# COMPUTE_CLUSTER_ARM_COREPACK_0_COMPUTE_CLUSTER_ARM_COREPACK_0_APBADDR_ETM_CPU1_000730140000h register map
Vendor: Texas Instruments
Peripheral module from a debugger description file (folder am62L).
Registers are 32-bit, read-write, reset 0x0 unless marked. A register's access mark holds for its fields unless they carry their own. Offsets are as the file gives them; lines under a group give offsets from that group; [hi:lo] are bit positions; {n}, {i} and the like mark numbered series; 'fields as' and 'values as' point back to an identical list; <NAME> marks a mode.

## COMPUTE_CLUSTER_ARM_COREPACK_0_APBADDR_ETM_CPU1 (part 1 of 2)
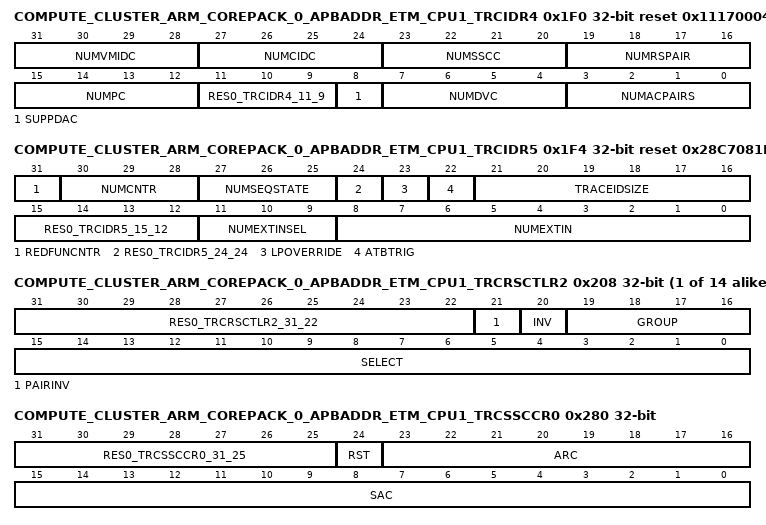
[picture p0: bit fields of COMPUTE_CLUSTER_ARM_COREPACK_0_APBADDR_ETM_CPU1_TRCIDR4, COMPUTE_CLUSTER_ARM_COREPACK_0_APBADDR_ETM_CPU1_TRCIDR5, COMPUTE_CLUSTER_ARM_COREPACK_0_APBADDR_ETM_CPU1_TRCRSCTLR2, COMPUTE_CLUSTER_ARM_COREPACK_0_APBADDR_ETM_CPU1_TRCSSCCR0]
0x1F0 COMPUTE_CLUSTER_ARM_COREPACK_0_APBADDR_ETM_CPU1_TRCIDR4 reset 0x11170004 — ID Register 4
  [31:28] NUMVMIDC — Indicates the number of VMID comparators that are available for tracing. The permitted values are: 0000 No VMID comparators are available. 0001 The implementation has one VMID comparator. 0010 The implementation has two VMID comparators. and so on up to 0b1000, which indicates that the implementation has eight VMID comparators.All other values are reserved.
  [27:24] NUMCIDC — Indicates the number of Context ID comparators that are available for tracing. The permitted values are: 0000 No Context ID comparators are available. 0001 The implementation has one Context ID comparator. 0010 The implementation has two Context ID comparators. and so on up to 0b1000, which indicates that the implementation has eight Context ID comparators.All other values are reserved.
  [23:20] NUMSSCC — Indicates the number of single-shot comparator controls that are available for tracing. The permitted values are: 0000 No single-shot comparator controls are available. 0001 The implementation has one single-shot comparator control. 0010 The implementation has two single-shot comparator controls. and so on up to 0b1000, which indicates that the implementation has eight single-shot comparator controls.All other values are reserved.
  [19:16] NUMRSPAIR — Indicates the number of resource selection pairs that are available for tracing. The permitted values are: 0000 The implementation has one resource selection pair. 0001 The implementation has two resource selection pairs. 0010 The implementation has three resource selection pairs. and so on up to 0b1111, which indicates that the implementation has 16 resource selection pairs.Implementations always have at least one resource selection pair so that they can support the FALSE and TRUE resource selectors, 0 and 1.
  [15:12] NUMPC — Indicates the number of processor comparator inputs that are available for tracing. The permitted values are: 0000 No processor comparator inputs are available. 0001 The implementation has one processor comparator input. 0010 The implementation has two processor comparator inputs. and so on up to 0b1000, which indicates that the implementation has eight processor comparator inputs.All other values are reserved.
  [11:9] RES0_TRCIDR4_11_9 — Reserved, RES0.
  [8] SUPPDAC — Indicates if the implementation can support data address comparisons: 0 The implementation does not support data address comparisons. 1 The implementation can support data address comparisons
  [7:4] NUMDVC — Indicates the number of data value comparators that are available for tracing. The permitted values are: 0000 No data value comparators are available. 0001 The implementation has one data value comparator. 0010 The implementation has two data value comparators. and so on up to 0b1000, which indicates that the implementation has eight data value comparators.All other values are reserved.
  [3:0] NUMACPAIRS — Indicates the number of address comparator pairs that are available for tracing. The permitted values are: 0000 No address comparator pairs are available. 0001 The implementation has one address comparator pair. 0010 The implementation has two address comparator pairs. and so on up to 0b1000, which indicates that the implementation has eight address comparator pairs.All other values are reserved.
0x1F4 COMPUTE_CLUSTER_ARM_COREPACK_0_APBADDR_ETM_CPU1_TRCIDR5 reset 0x28C7081E — ID Register 5
  [31] REDFUNCNTR — Indicates if the reduced function counter is implemented: 0 The reduced function counter is not supported. 1 Counter 0 is implemented as a reduced function counter.
  [30:28] NUMCNTR — Indicates the number of counters that are available for tracing. The permitted values are: 000 No counters are available. 001 The implementation has one counter. 010 The implementation has two counters. 011 The implementation has three counters. 100 The implementation has four counters. All other values are reserved.
  [27:25] NUMSEQSTATE — Indicates the number of sequencer states that are implemented. The permitted values are: 000 No sequencer states are implemented. 100 The implementation has four sequencer states. All other values are reserved.
  [24] RES0_TRCIDR5_24_24 — Reserved, RES0.
  [23] LPOVERRIDE — Indicates if the implementation can support low-power state override: 0 The implementation does not support low-power state override. 1 The implementation supports low-power state override, and the TRCEVENTCTL1R.LPOVERRIDE field is implemented. The trace unit must support low-power state override if it can enter a low-power mode where the resources and event trace generation are disabled.
  [22] ATBTRIG — Indicates if the implementation can support ATB triggers: 0 The implementation does not support ATB triggers. 1 The implementation supports ATB triggers, and the TRCEVENTCTL1R.ATBTRIG field is implemented.
  [21:16] TRACEIDSIZE — Indicates the trace ID width. The permitted value is: 111 The implementation supports a 7-bit trace ID. This sets the width of the TRCTRACEIDR.TRACEID field. All other values are reserved.The CoreSight ATB requires a 7-bit trace ID width.
  [15:12] RES0_TRCIDR5_15_12 — Reserved, RES0.
  [11:9] NUMEXTINSEL — Indicates how many external input select resources are implemented. The permitted values are: 000 No external input select resources are available. If NUMEXTINSEL is zero, NUMEXTIN must also be zero. 001 The implementation has one external input select resource. 010 The implementation has two external input select resources. 011 The implementation has three external input select resources. 100 The implementation has four external input select resources. All other values are reserved.See TRCEXTINSELR for how to select an input select resource.
  [8:0] NUMEXTIN — Indicates how many external inputs are implemented. The permitted values are: 000000000 No external inputs are available. If NUMEXTIN is zero, NUMEXTINSEL must also be zero. 000000001 The implementation has one external input. 000000010 The implementation has two external inputs. and so on up to 0b100000000, which indicates that the implementation has 256 external inputs.All other values >0b100000000 are reserved.See TRCEXTINSELR for how to select an external input.
{0x200+4i} COMPUTE_CLUSTER_ARM_COREPACK_0_APBADDR_ETM_CPU1_TRCRSCTLR{i} (i=2..15) — Resource Selection Control Registers {i}
  [31:22] RES0_TRCRSCTLR{i}_31_22 — Reserved, RES0.
  [21] PAIRINV — If n is an even number, controls whether the combined result from a resource pair is inverted: 0 The combined result is not inverted. 1 The combined result is inverted. If n is an odd number, this field is RES0.
  [20] INV — Controls whether the resource that GROUP and SELECT selects is inverted: 0 The selected resource is not inverted. 1 The selected resource is inverted.
  [19:16] GROUP — Selects a group of resources. Possible values are: 0000 For SELECT bits 0 to 3, selects external input selector 0 to 3; other bits are reserved. 0001 For SELECT bits 0 to 7, selects processor comparator inputs 0 to 7; other bits are reserved. 0010 For SELECT bits 0 to 3, selects counter at zero 0 to 3; for SELECT bits 4 to 7, selects sequencer states 0 to 3; other bits are reserved. 0011 For SELECT bits 0 to 7, selects single-shot comparator control 0 to 7; other bits are reserved. 0100 For SELECT bits 0 to 15, selects single address comparator 0 to 15. 0101 For SELECT bits 0 to 7, selects address range comparator 0 to 7; other bits are reserved. 0110 For SELECT bits 0 to 7, selects Context ID comparator 0 to 7; other bits are reserved. 0111 For SELECT bits 0 to 7, selects VMID comparator 0 to 7; other bits are reserved. All other values are reserved.
  [15:0] SELECT — Selects one or more resources from the group that the GROUP field selects. Each bit represents a resource from the selected group.See the GROUP field description for details.
0x280 COMPUTE_CLUSTER_ARM_COREPACK_0_APBADDR_ETM_CPU1_TRCSSCCR0 — Single-Shot Comparator Control Register 0
  [31:25] RES0_TRCSSCCR0_31_25 — Reserved, RES0.
  [24] RST — Controls whether the single-shot comparator resource is reset when it fires. 0 When the single-shot comparator resource fires, it is not reset. 1 When the single-shot comparator resource fires, it is reset. This enables the single-shot comparator resource to fire multiple times.
  [23:16] ARC — Selects one or more address range comparators for single-shot control.Each bit represents an address range comparator pair, so bit[n-16] controls the selection of address range comparator pair n-16. If bit[n-16] is: 0 The address range comparator pair n-16 is not selected for single-shot control. 1 The address range comparator pair n-16 is selected for single-shot control. The width of this field is IMPLEMENTATION DEFINED. The field contains a number of implemented bits equal to TRCIDR4.NUMACPAIRS. Unimplemented bits are RAZ/WI.
  [15:0] SAC — Selects one or more single address comparators for single-shot control.Each bit represents a single address comparator, so bit[n] controls the selection of single address comparator n. If bit[n] is: 0 The single address comparator n, is not selected for single-shot control. 1 The single address comparator n, is selected for single-shot control. The width of this field is IMPLEMENTATION DEFINED. The field contains a number of implemented bits equal to 2 x TRCIDR4.NUMACPAIRS. Unimplemented bits are RAZ/WI.
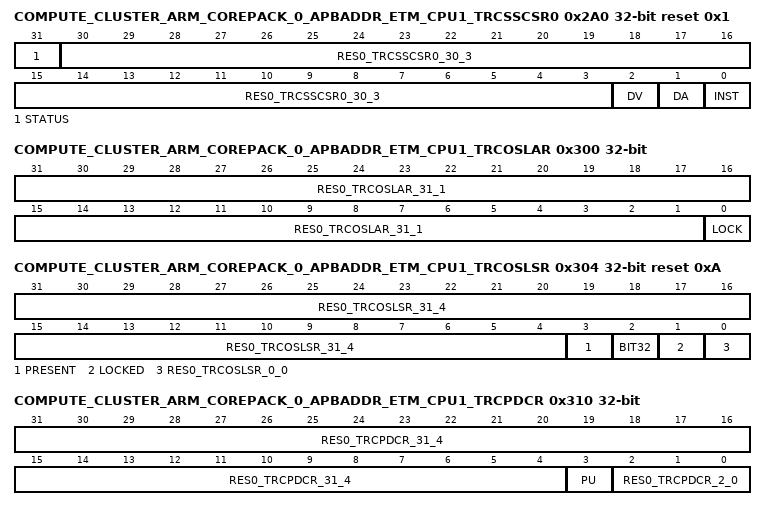
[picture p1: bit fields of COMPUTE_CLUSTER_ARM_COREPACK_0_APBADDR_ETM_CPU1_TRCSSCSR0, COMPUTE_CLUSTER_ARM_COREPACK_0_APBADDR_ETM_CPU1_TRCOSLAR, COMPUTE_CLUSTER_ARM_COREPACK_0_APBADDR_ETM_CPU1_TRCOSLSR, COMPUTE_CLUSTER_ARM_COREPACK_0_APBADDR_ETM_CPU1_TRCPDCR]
0x2A0 COMPUTE_CLUSTER_ARM_COREPACK_0_APBADDR_ETM_CPU1_TRCSSCSR0 reset 0x1 — Single-Shot Comparator Status Register 0
  [31] STATUS — Single-shot status bit. Indicates if any of the comparators that TRCSSCCRn.SAC or TRCSSCCRn.ARC selects have matched: 0 No match has occurred. 1 One or more matches has occurred. If TRCSSCCRn.RST==0 then there is only one match and no more matches are possible, and software must reset this bit to 0 to re-enable the single-shot control. STATUS must be written to set an initial state when configuring the trace unit, if the single-shot comparator is to be used.
  [30:3] RES0_TRCSSCSR0_30_3 — Reserved, RES0.
  [2] DV — Data value comparator support bit. Indicates if the trace unit supports data address with data value comparisons: 0 Single-shot data address with data value comparisons are not supported. 1 Single-shot data address with data value comparisons are supported.
  [1] DA — Data address comparator support bit. Indicates if the trace unit supports data address comparisons: 0 Single-shot data address comparisons are not supported. 1 Single-shot data address comparisons are supported.
  [0] INST — Instruction address comparator support bit. Indicates if the trace unit supports instruction address comparisons: 0 Single-shot instruction address comparisons are not supported. 1 Single-shot instruction address comparisons are supported.
0x300 COMPUTE_CLUSTER_ARM_COREPACK_0_APBADDR_ETM_CPU1_TRCOSLAR — OS Lock Access Register
  [31:1] RES0_TRCOSLAR_31_1 — Reserved, RES0.
  [0] LOCK — OS Lock control bit: 0 Unlocks the OS Lock. 1 Locks the OS Lock. This setting disables the trace unit.
0x304 COMPUTE_CLUSTER_ARM_COREPACK_0_APBADDR_ETM_CPU1_TRCOSLSR reset 0xA — OS Lock Status Register
  [31:4] RES0_TRCOSLSR_31_4 — Reserved, RES0.
  [3] PRESENT — Indicates whether the OS Lock is implemented.This bit is RES1, which indicates that the OS Lock is always implemented.
  [2] BIT32 — This bit is RES0, which indicates that software must perform a 32-bit write to update the TRCOSLAR.
  [1] LOCKED — OS Lock status bit: 0 The OS Lock is unlocked. 1 The OS Lock is locked. When the trace unit core power domain is powered down the value is UNKNOWN. The TRCPDSR indicates if the trace unit core power domain is powered down.
  [0] RES0_TRCOSLSR_0_0 — Reserved, RES0.
0x310 COMPUTE_CLUSTER_ARM_COREPACK_0_APBADDR_ETM_CPU1_TRCPDCR — Power Down Control Register
  [31:4] RES0_TRCPDCR_31_4 — Reserved, RES0.
  [3] PU — Powerup request bit: 0 The system can remove power from the trace unit. The TRCPDSR indicates if the trace unit is powered down. 1 The system must provide power to the trace unit. Typically, a trace unit drives a signal representing the value of this bit to a power controller to request that the trace unit core power domain is powered up. However, if the trace unit and the processor are in the same power domain then the implementation might combine the PU status with a signal from the processor.
  [2:0] RES0_TRCPDCR_2_0 — Reserved, RES0.
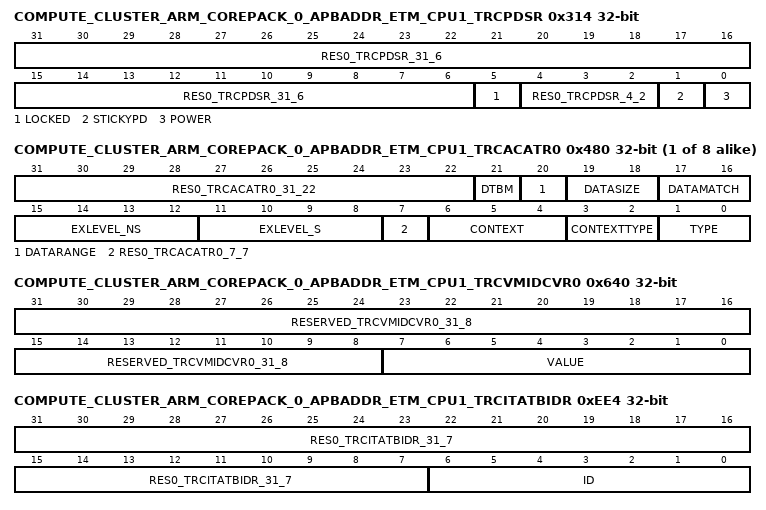
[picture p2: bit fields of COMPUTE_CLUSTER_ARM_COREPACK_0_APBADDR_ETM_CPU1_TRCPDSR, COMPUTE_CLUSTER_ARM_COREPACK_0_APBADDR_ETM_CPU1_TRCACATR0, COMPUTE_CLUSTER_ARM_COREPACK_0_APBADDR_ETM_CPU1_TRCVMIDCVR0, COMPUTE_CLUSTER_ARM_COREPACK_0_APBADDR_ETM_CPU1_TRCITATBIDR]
0x314 COMPUTE_CLUSTER_ARM_COREPACK_0_APBADDR_ETM_CPU1_TRCPDSR — Power Down Status Register
  [31:6] RES0_TRCPDSR_31_6 — Reserved, RES0.
  [5] LOCKED — OS Lock status bit: 0 The OS Lock is unlocked. 1 The OS Lock is locked. The value is UNKNOWN when the trace unit core power domain is powered down, that is, when POWER==0.
  [4:2] RES0_TRCPDSR_4_2 — Reserved, RES0.
  [1] STICKYPD — Sticky powerdown status bit. Indicates whether the trace register state is valid: 0 If POWER==1 then the state of TRCOSLSR and the trace registers are valid. If POWER==0 then it is UNKNOWN whether the state of TRCOSLSR and the trace registers are valid. 1 The state of TRCOSLSR and the trace registers might not be valid. The trace unit sets this bit to 1 if either the trace unit is reset, or the power to the trace unit core power domain is removed and the trace register state is not valid. After this register is read, if the Software Lock is unlocked and the trace unit core power domain is powered up, then the trace unit sets this bit to 0. The TRCLAR controls whether the Software Lock is locked.
  [0] POWER — Power status bit: 0 The trace unit core power domain is not powered. The trace registers are not accessible and they all return an error response. 1 The trace unit core power domain is powered. The trace registers are accessible.
{0x400+8i} COMPUTE_CLUSTER_ARM_COREPACK_0_APBADDR_ETM_CPU1_TRCACVR{i}_31_0 (i=0..7) — Address Comparator Value Registers {i} (low word)
  [31:0] ADDRESS — Address value.The address comparators can support implementations that use multiple address widths. When the trace unit compares the ADDRESS field with an address that has a width less than this field, then it must ignore those upper bits in the comparison. For example, in a system that supports both 32-bit and 64-bit addresses, when the processor is in 32-bit state the comparator must ignore the ADDRESS[63_32] bits.
{0x404+8i} COMPUTE_CLUSTER_ARM_COREPACK_0_APBADDR_ETM_CPU1_TRCACVR{i}_63_32 (i=0..7) — Address Comparator Value Registers {i} (high word)
  fields as COMPUTE_CLUSTER_ARM_COREPACK_0_APBADDR_ETM_CPU1_TRCACVR0_31_0
{0x480+8i} COMPUTE_CLUSTER_ARM_COREPACK_0_APBADDR_ETM_CPU1_TRCACATR{i} (i=0..7) — Address Comparator Access Type Registers {i}
  [31:22] RES0_TRCACATR{i}_31_22 — Reserved, RES0.
  [21] DTBM — Controls whether data address comparisons use the data address [63:56] bits: 0 The trace unit ignores the data address [63:56] bits for data address comparisons. 1 The trace unit uses the data address [63:56] bits for data address comparisons. Supported only if TRCIDR2.DASIZE indicates that the data address size is 64 bits, otherwise this bit is RES0.
  [20] DATARANGE — Controls whether a data value comparison uses the single address comparator or the address range comparator: 0 The trace unit uses the single address comparator for data value comparisons. The behavior of the address range comparator is UNPREDICTABLE. 1 The trace unit uses the address range comparator for data value comparisons. The behavior of the single address comparators in this pair is UNPREDICTABLE. The trace unit ignores this field when DATAMATCH==0b00.Supported only if the corresponding data value comparator is supported, otherwise this bit is RES0.
  [19:18] DATASIZE — Controls the width of the data value comparison: 00 Byte. 01 Halfword. 10 Word. 11 Doubleword. Supported only if the corresponding data value comparator is supported, otherwise this field is RES0.The doubleword width is supported only if TRCIDR2.DVSIZE indicates that 64-bit values are supported. If 64-bit values are not supported, 0b11 is reserved.
  [17:16] DATAMATCH — Controls how the trace unit performs a data value comparison: 00 The trace unit does not perform a data value comparison. 01 The trace unit performs a data value comparison and signals a match if both values are identical. 10 Reserved. 11 The trace unit performs a data value comparison and signals a match if both values are different. Supported only if the corresponding data value comparator is supported, otherwise this field is RES0.
  [15:12] EXLEVEL_NS — In Non-secure state, each bit controls whether a comparison can occur for the corresponding exception level: 0 The trace unit can perform a comparison, in Non-secure state, for exception level n. 1 The trace unit does not perform a comparison, in Non-secure state, for exception level n. The exception levels are:Bit[12]Exception level 0.Bit[13]Exception level 1.Bit[14]Exception level 2.Bit[15]RAZ/WI. EXLEVEL_NS[3] is never implemented.The content of the field is IMPLEMENTATION DEFINED and is set by the value of TRCIDR3.EXLEVEL_NS. Unimplemented bits are RAZ/WI.
  [11:8] EXLEVEL_S — In Secure state, each bit controls whether a comparison can occur for the corresponding exception level: 0 The trace unit can perform a comparison, in Secure state, for exception level n. 1 The trace unit does not perform a comparison, in Secure state, for exception level n. The exception levels are:Bit[8]Exception level 0.Bit[9]Exception level 1.Bit[10]RAZ/WI. EXLEVEL_S[2] is never implemented.Bit[11]Exception level 3.The content of the field is IMPLEMENTATION DEFINED and is set by the value of TRCIDR3.EXLEVEL_S. Unimplemented bits are RAZ/WI.
  [7] RES0_TRCACATR{i}_7_7 — Reserved, RES0.
  [6:4] CONTEXT — If TRCIDR4.NUMCIDFC > 0 or TRCIDR4.NUMVMIDC > 0, selects a Context ID comparator or VMID comparator: 000 Comparator 0. 001 Comparator 1. 010 Comparator 2. and so on up to 0b111, which indicates comparator 7.The implemented width of this field is determined by the size of whichever of TRCIDR4.NUMVMIDC and TRCIDR4.NUMCIDC is larger. If the largest field is one bit long, then this field implements one bit, bit[4]. If the largest field is four bits long, then this field implements two bits, bits[5:4]. Unimplemented bits within the field are RAZ/WI.If TRCIDR4.NUMCIDFC==0 and TRCIDR4.NUMVMIDC==0, this field is RES0.
  [3:2] CONTEXTTYPE — If TRCIDR4.NUMVMIDC>0 and TRCIDR4.NUMCIDC>0, this field controls whether the trace unit performs a Context ID comparison, a virtual machine identifier [VMID] comparison, or both comparisons: 00 The trace unit does not perform a Context ID or VMID comparison. 01 The trace unit performs a Context ID comparison using the Context ID comparator that the CONTEXT field specifies, and signals a match if both the Context ID comparator matches and the address comparator match. 10 The trace unit performs a VMID comparison using the VMID comparator that the CONTEXT field specifies, and signals a match if both the VMID comparator and the address comparator match. 11 The trace unit performs a Context ID comparison and a VMID comparison using the comparators that the CONTEXT field specifies, and signals a match if the Context ID comparator matches, the VMID comparator matches, and the address comparator matches. If TRCIDR4.NUMVMIDC==0 and TRCIDR4.NUMCIDC>0, bit [3] is RES0 and bit[2] controls whether the trace unit performs a Context ID comparison, as with cases 0b00 and 0b01 above.If TRCIDR4.NUMVMIDC==0 and TRCIDR4.NUMCIDC==0, both bits are RES0.
  [1:0] TYPE — Controls what type of comparison the trace unit performs: 00 Instruction address. 01 Data load address. 10 Data store address. 11 Data load address or data store address. If TRCIDR4.SUPPDAC does not indicate that data address comparisons are implemented, then this field is RES0. This means that any comparison performed by this address comparator is an instruction address comparison.
0x600 COMPUTE_CLUSTER_ARM_COREPACK_0_APBADDR_ETM_CPU1_TRCCIDCVR0 — Context ID Comparator Value Register 0
  [31:0] VALUE — Context ID value. The implemented width of this field is IMPLEMENTATION DEFINED and is set by TRCIDR2.CIDSIZE. Unimplemented bits are RAZ/WI.After a processor reset, the ETM architecture assumes that the Context ID is zero until the processor updates the Context ID.
0x640 COMPUTE_CLUSTER_ARM_COREPACK_0_APBADDR_ETM_CPU1_TRCVMIDCVR0 — VMID Comparator Value Register 0
  [31:8] RESERVED_TRCVMIDCVR0_31_8 — Reserved RES0
  [7:0] VALUE — Contains a VMID value.
0x680 COMPUTE_CLUSTER_ARM_COREPACK_0_APBADDR_ETM_CPU1_TRCCIDCCTLR0 — Context ID Comparator Control Register 0
  [31:0] COMP_N — Controls the mask value that the trace unit applies to TRCCIDCVRn. Each bit in this field corresponds to a byte in TRCCIDCVRn. When a bit is: 0 The trace unit includes the relevant byte in TRCCIDCVRn when it performs the Context ID comparison. 1 The trace unit ignores the relevant byte in TRCCIDCVRn when it performs the Context ID comparison. Supported only if TRCIDR4.NUMCIDC > n, otherwise the field is RES0.
0xEE4 COMPUTE_CLUSTER_ARM_COREPACK_0_APBADDR_ETM_CPU1_TRCITATBIDR — Integration ATB Identification Register
  [31:7] RES0_TRCITATBIDR_31_7 — Reserved RES0
  [6:0] ID — Drives the ATIDMn[6:0] output pins
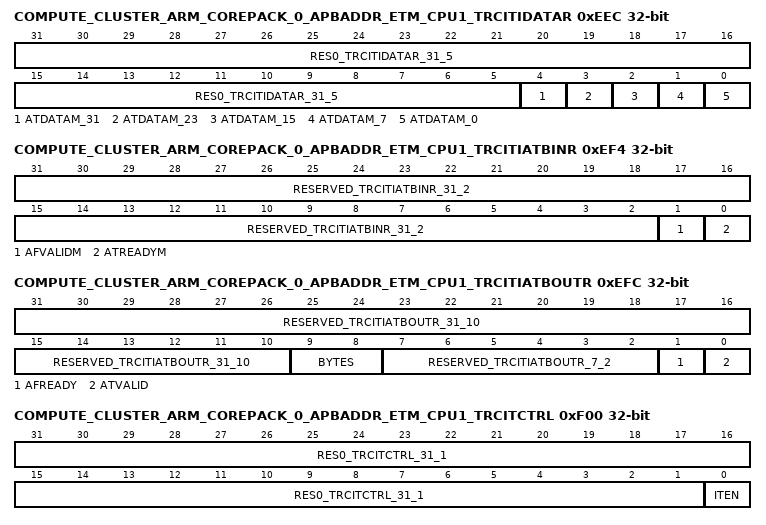
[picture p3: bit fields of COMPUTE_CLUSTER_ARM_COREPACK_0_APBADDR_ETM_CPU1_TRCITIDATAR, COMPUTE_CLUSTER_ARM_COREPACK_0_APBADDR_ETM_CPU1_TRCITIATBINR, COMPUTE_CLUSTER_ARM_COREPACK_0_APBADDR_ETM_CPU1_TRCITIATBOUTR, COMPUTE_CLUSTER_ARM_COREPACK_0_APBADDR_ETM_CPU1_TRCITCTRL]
0xEEC COMPUTE_CLUSTER_ARM_COREPACK_0_APBADDR_ETM_CPU1_TRCITIDATAR — Integration Instruction ATB Data Register
  [31:5] RES0_TRCITIDATAR_31_5 — Reserved RES0
  [4] ATDATAM_31 — Drives the ATDATAM[31] output
  [3] ATDATAM_23 — Drives the ATDATAM[23] output
  [2] ATDATAM_15 — Drives the ATDATAM[15] output
  [1] ATDATAM_7 — Drives the ATDATAM[7] output
  [0] ATDATAM_0 — Drives the ATDATAM[0] output
0xEF4 COMPUTE_CLUSTER_ARM_COREPACK_0_APBADDR_ETM_CPU1_TRCITIATBINR — Integration Instruction ATB In Register
  [31:2] RESERVED_TRCITIATBINR_31_2 — Reserved. Read undefined.
  [1] AFVALIDM — Returns the value of the AFVALIDMn input pin
  [0] ATREADYM — Returns the value of the ATREADYMn input pin
0xEFC COMPUTE_CLUSTER_ARM_COREPACK_0_APBADDR_ETM_CPU1_TRCITIATBOUTR — Integration Instruction ATB Out Register
  [31:10] RESERVED_TRCITIATBOUTR_31_10 — Reserved. Read undefined.
  [9:8] BYTES — Drives the ATBYTESMn[1:0] output pins
  [7:2] RESERVED_TRCITIATBOUTR_7_2 — Reserved. Read undefined.
  [1] AFREADY — Drives the AFREADYMn output pin
  [0] ATVALID — Drives the ATVALIDMn output pin
0xF00 COMPUTE_CLUSTER_ARM_COREPACK_0_APBADDR_ETM_CPU1_TRCITCTRL — Integration Mode Control Register
  [31:1] RES0_TRCITCTRL_31_1 — Reserved, RES0.
  [0] ITEN — Integration mode enable bit: 0 The trace unit is not in integration mode. 1 The trace unit is in integration mode. This mode enables a debug agent to perform topology detection, and System-on-Chip [SoC] test software to perform integration testing.
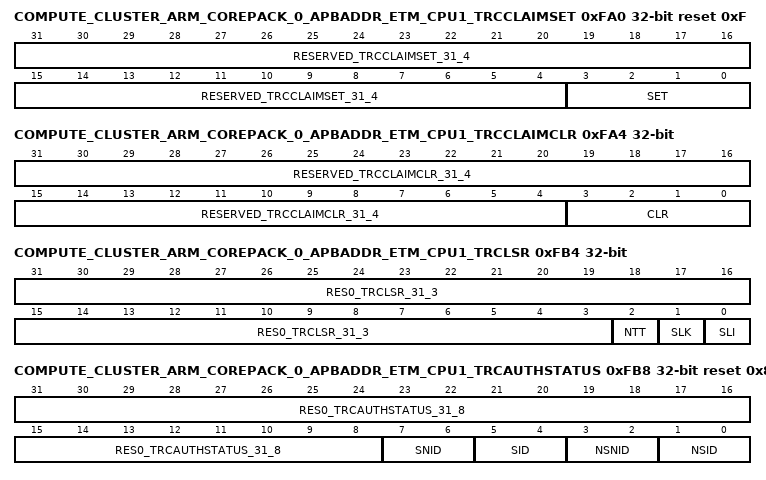
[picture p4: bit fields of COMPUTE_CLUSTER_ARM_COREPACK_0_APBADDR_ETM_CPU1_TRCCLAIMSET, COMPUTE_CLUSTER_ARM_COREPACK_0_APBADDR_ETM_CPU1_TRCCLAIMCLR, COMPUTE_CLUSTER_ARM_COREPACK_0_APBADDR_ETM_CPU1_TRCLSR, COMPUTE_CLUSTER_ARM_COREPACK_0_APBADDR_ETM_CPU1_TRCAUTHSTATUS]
0xFA0 COMPUTE_CLUSTER_ARM_COREPACK_0_APBADDR_ETM_CPU1_TRCCLAIMSET reset 0xF — Claim Tag Set Register
  [31:4] RESERVED_TRCCLAIMSET_31_4 — Reserved RES0
  [3:0] SET — Sets bits in the claim tag and determines the number of claim tag bits implemented.
0xFA4 COMPUTE_CLUSTER_ARM_COREPACK_0_APBADDR_ETM_CPU1_TRCCLAIMCLR — Claim Tag Clear Register
  [31:4] RESERVED_TRCCLAIMCLR_31_4 — Reserved RES0
  [3:0] CLR — Clears bits in the claim tag and determines the current value of the claim tag.
0xFA8 COMPUTE_CLUSTER_ARM_COREPACK_0_APBADDR_ETM_CPU1_TRCDEVAFF0 reset 0x80000001 — Device Affinity Register 0
  [31:0] MPIDR_EL1_31_0 — Read-only copy of the low half of MPIDR_EL1, as seen from the highest implemented exception level.
0xFAC COMPUTE_CLUSTER_ARM_COREPACK_0_APBADDR_ETM_CPU1_TRCDEVAFF1 — Device Affinity Register 1
  [31:0] MPIDR_EL1_63_32 — Read-only copy of the high half of MPIDR_EL1, as seen from the highest implemented exception level.
0xFB0 COMPUTE_CLUSTER_ARM_COREPACK_0_APBADDR_ETM_CPU1_TRCLAR — Software Lock Access Register
  [31:0] KEY — Writing the key value 0xC5ACCE55 to this field clears the lock, enabling write accesses to this component's registers through a memory-mapped interface.Writing any other value to this register sets the lock, disabling write accesses to this component's registers through a memory mapped interface.Software can use the Software Lock to prevent accidental modification of the trace unit registers by software being debugged. For example, software that accidentally initializes an incorrect region of memory might disable the trace unit and make it impossible to trace the software.
0xFB4 COMPUTE_CLUSTER_ARM_COREPACK_0_APBADDR_ETM_CPU1_TRCLSR — Software Lock Status Register
  [31:3] RES0_TRCLSR_31_3 — Reserved, RES0.
  [2] NTT — Not thirty-two bit access required. RAZ.
  [1] SLK — Software lock status for this component. Possible values of this field are: 0 Lock clear. Writes are permitted to this component's registers. 1 Lock set. Writes to this component's registers are ignored, and reads have no side effects.
  [0] SLI — Software lock implemented. RAO.
0xFB8 COMPUTE_CLUSTER_ARM_COREPACK_0_APBADDR_ETM_CPU1_TRCAUTHSTATUS reset 0x88 — Authentication Status Register
  [31:8] RES0_TRCAUTHSTATUS_31_8 — Reserved, RES0.
  [7:6] SNID — Indicates whether the system enables the trace unit to support Secure non-invasive debug: 00 The trace unit does not implement support for Secure non-invasive debug. 01 Reserved. 10 Secure non-invasive debug is disabled. 11 Secure non-invasive debug is enabled.
  [5:4] SID — Indicates whether the trace unit supports Secure invasive debug: 00 The trace unit does not support Secure invasive debug. All other values are reserved.
  [3:2] NSNID — Indicates whether the system enables the trace unit to support Non-secure non-invasive debug: 00 The trace unit does not implement support for Non-secure non-invasive debug. 01 Reserved. 10 Non-secure non-invasive debug is disabled. 11 Non-secure non-invasive debug is enabled.
  [1:0] NSID — Indicates whether the trace unit supports Non-secure invasive debug: 00 The trace unit does not support Non-secure invasive debug. All other values are reserved.
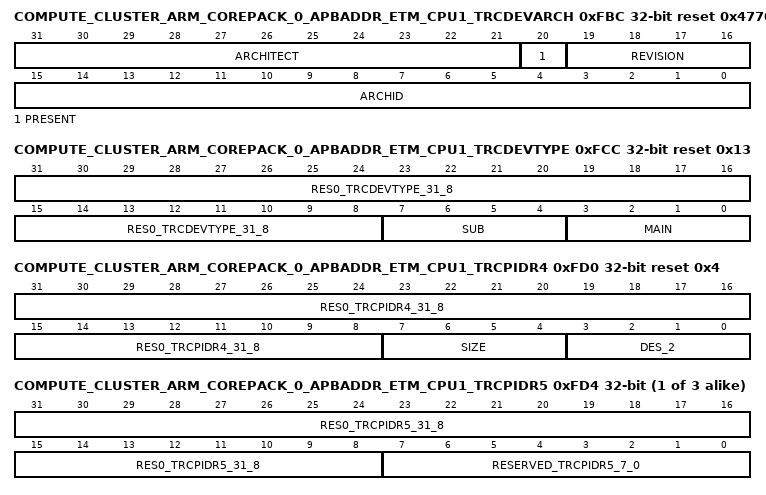
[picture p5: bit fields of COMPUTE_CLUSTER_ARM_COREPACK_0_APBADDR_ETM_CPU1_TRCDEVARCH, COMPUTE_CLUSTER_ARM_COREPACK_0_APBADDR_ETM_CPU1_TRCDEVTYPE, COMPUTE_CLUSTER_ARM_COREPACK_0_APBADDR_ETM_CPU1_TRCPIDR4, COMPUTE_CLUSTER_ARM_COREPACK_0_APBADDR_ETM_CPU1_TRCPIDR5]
0xFBC COMPUTE_CLUSTER_ARM_COREPACK_0_APBADDR_ETM_CPU1_TRCDEVARCH reset 0x47704A13 — Device Architecture Register
  [31:21] ARCHITECT — Defines the architecture of the component. For trace, this is ARM Limited.Bits [31:28] are the JEP 106 continuation code, 0x4.Bits [27:21] are the JEP 106 ID code, 0x3B.
  [20] PRESENT — When set to 1, indicates that the DEVARCH is present.This field is RAO.
  [19:16] REVISION — Defines the architecture revision. For architectures defined by ARM this is the minor revision.For trace, the revision defined by ETMv4 is 0x0.All other values are reserved.
  [15:0] ARCHID — Defines this part to be a v8-A debug component. For architectures defined by ARM this is further subdivided.For trace, bits [15:12] are the architecture version, 0x4; bits [11:0] are the architecture part number, 0xA13.This corresponds to trace architecture version ETMv4.
0xFC8 COMPUTE_CLUSTER_ARM_COREPACK_0_APBADDR_ETM_CPU1_TRCDEVID — Device ID Register
  [31:0] DEVID — Indicates the capabilities of the trace unit. The implemented width of this field and its bit assignments are IMPLEMENTATION DEFINED. Unimplemented bits are RAZ/WI.If a component is configurable then ARM recommends that this field can also indicate which configuration options are implemented that differ from the standard configuration.
0xFCC COMPUTE_CLUSTER_ARM_COREPACK_0_APBADDR_ETM_CPU1_TRCDEVTYPE reset 0x13 — Device Type Register
  [31:8] RES0_TRCDEVTYPE_31_8 — Reserved, RES0.
  [7:4] SUB — Returns 0x1, to indicate that the ETM generates processor trace.All other values are reserved.
  [3:0] MAIN — Returns 0x3, to indicate that the ETM is a trace source.All other values are reserved.
0xFD0 COMPUTE_CLUSTER_ARM_COREPACK_0_APBADDR_ETM_CPU1_TRCPIDR4 reset 0x4 — Peripheral Identification Register 4
  [31:8] RES0_TRCPIDR4_31_8 — Reserved, RES0.
  [7:4] SIZE — Size of the component. RES0. This indicates that the ETM memory map occupies 4KB.
  [3:0] DES_2 — Designer, JEP106 continuation code. For ARM Limited, this field is 0b0100.
{0xFC0+4i} COMPUTE_CLUSTER_ARM_COREPACK_0_APBADDR_ETM_CPU1_TRCPIDR{i} (i=5..7) — Peripheral Identification Register {i}
  [31:8] RES0_TRCPIDR{i}_31_8 — Reserved, RES0.
  [7:0] RESERVED_TRCPIDR{i}_7_0 — RES0, reserved for future use.
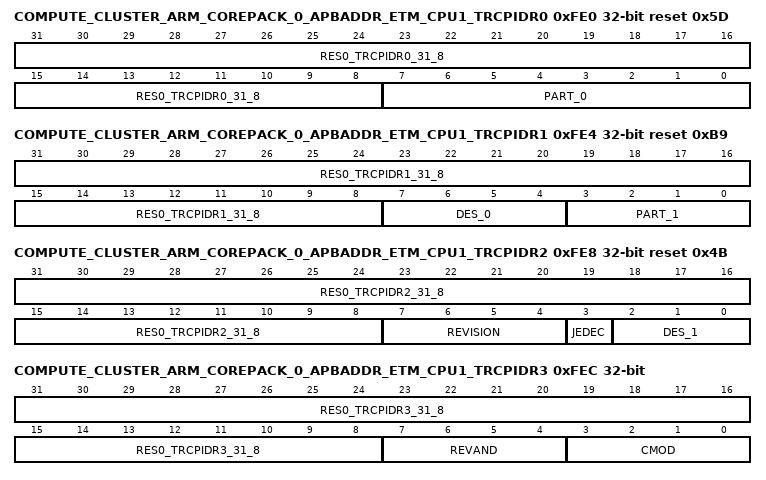
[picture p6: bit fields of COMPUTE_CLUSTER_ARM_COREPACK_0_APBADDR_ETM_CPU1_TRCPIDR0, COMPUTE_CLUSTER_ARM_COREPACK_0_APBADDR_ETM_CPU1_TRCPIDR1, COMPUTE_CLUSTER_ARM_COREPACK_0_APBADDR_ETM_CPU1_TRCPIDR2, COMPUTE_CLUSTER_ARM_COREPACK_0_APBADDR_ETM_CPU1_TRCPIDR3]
0xFE0 COMPUTE_CLUSTER_ARM_COREPACK_0_APBADDR_ETM_CPU1_TRCPIDR0 reset 0x5D — Peripheral Identification Register 0
  [31:8] RES0_TRCPIDR0_31_8 — Reserved, RES0.
  [7:0] PART_0 — Part number, bits[7:0].
0xFE4 COMPUTE_CLUSTER_ARM_COREPACK_0_APBADDR_ETM_CPU1_TRCPIDR1 reset 0xB9 — Peripheral Identification Register 1
  [31:8] RES0_TRCPIDR1_31_8 — Reserved, RES0.
  [7:4] DES_0 — Designer, bits[3:0] of JEP106 ID code. For ARM Limited, this field is 0b1011.
  [3:0] PART_1 — Part number, bits[11:8].
0xFE8 COMPUTE_CLUSTER_ARM_COREPACK_0_APBADDR_ETM_CPU1_TRCPIDR2 reset 0x4B — Peripheral Identification Register 2
  [31:8] RES0_TRCPIDR2_31_8 — Reserved, RES0.
  [7:4] REVISION — The IMPLEMENTATION DEFINED revision number for the ETM implementation. See also TRCIDR1.REVISION.
  [3] JEDEC — RAO. Indicates a JEP106 identity code is used.
  [2:0] DES_1 — Designer, most significant bits of JEP106 ID code. For ARM Limited, this field is 0b011.
0xFEC COMPUTE_CLUSTER_ARM_COREPACK_0_APBADDR_ETM_CPU1_TRCPIDR3 — Peripheral Identification Register 3
  [31:8] RES0_TRCPIDR3_31_8 — Reserved, RES0.
  [7:4] REVAND — The IMPLEMENTATION DEFINED manufacturing revision number for the implementation. After silicon is available, if metal fixes are necessary, the manufacturer can alter the top metal layer so that this field can indicate any post-fab silicon changes.
  [3:0] CMOD — Customer modified. Indicates someone other than the Designer has modified the component.
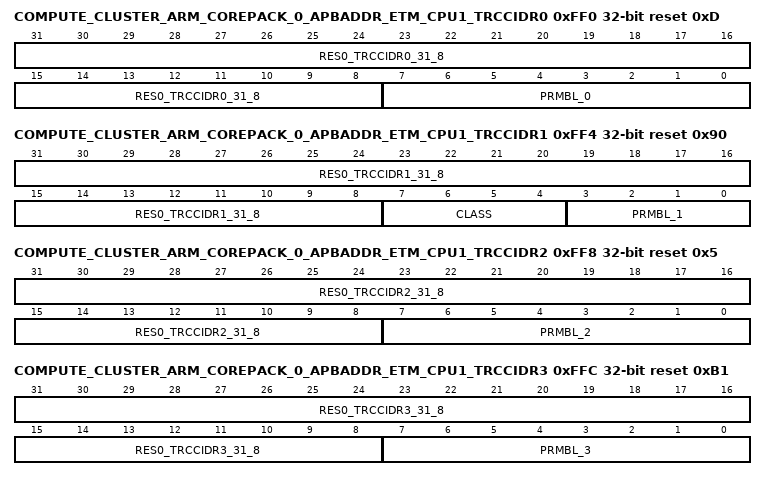
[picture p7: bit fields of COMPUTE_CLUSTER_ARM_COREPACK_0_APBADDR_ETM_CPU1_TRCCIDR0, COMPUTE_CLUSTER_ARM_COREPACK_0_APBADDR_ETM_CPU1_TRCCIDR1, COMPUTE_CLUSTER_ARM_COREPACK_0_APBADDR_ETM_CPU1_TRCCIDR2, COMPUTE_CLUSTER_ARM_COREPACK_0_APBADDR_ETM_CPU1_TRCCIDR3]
0xFF0 COMPUTE_CLUSTER_ARM_COREPACK_0_APBADDR_ETM_CPU1_TRCCIDR0 reset 0xD — Component Identification Register 0
  [31:8] RES0_TRCCIDR0_31_8 — Reserved, RES0.
  [7:0] PRMBL_0 — Preamble. Must read as 0x0D.
0xFF4 COMPUTE_CLUSTER_ARM_COREPACK_0_APBADDR_ETM_CPU1_TRCCIDR1 reset 0x90 — Component Identification Register 1
  [31:8] RES0_TRCCIDR1_31_8 — Reserved, RES0.
  [7:4] CLASS — Component class. Reads as 0x9, to indicate that the ETM is a debug component, with CoreSight architecture compliant management registers.
  [3:0] PRMBL_1 — Preamble. Must read as 0x0.
0xFF8 COMPUTE_CLUSTER_ARM_COREPACK_0_APBADDR_ETM_CPU1_TRCCIDR2 reset 0x5 — Component Identification Register 2
  [31:8] RES0_TRCCIDR2_31_8 — Reserved, RES0.
  [7:0] PRMBL_2 — Preamble. Must read as 0x05.
0xFFC COMPUTE_CLUSTER_ARM_COREPACK_0_APBADDR_ETM_CPU1_TRCCIDR3 reset 0xB1 — Component Identification Register 3
  [31:8] RES0_TRCCIDR3_31_8 — Reserved, RES0.
  [7:0] PRMBL_3 — Preamble. Must read as 0xB1.
